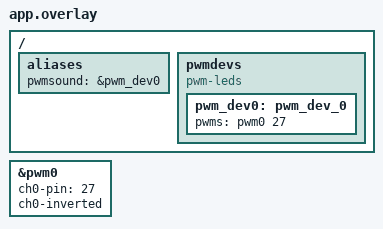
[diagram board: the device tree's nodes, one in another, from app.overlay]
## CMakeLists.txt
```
# SPDX-License-Identifier: Apache-2.0
#Setting to exclusively build for the Thingy
set(BOARD thingy52_nrf52832)
set(BOARD_FLASH_RUNNER jlink)
#set(DTC_OVERLAY_FILE boards/mpu9250.overlay)
set(CONF_FILE prj.conf)

cmake_minimum_required(VERSION 3.13.1)
#set(DTC_OVERLAY_FILE app.overlay)
find_package(Zephyr REQUIRED HINTS $ENV{ZEPHYR_BASE})
project(scu)

target_sources(app PRIVATE src/main.c 
        ../../oslib/scu_drivers/scu_ble/scu_ble.c
        #../../oslib/scu_drivers/scu_sensors/scu_sensors.c
        #../../oslib/scu_drivers/scu_io/scu_io.c
        )

#Add include_directories for libraries, path starts from this files location.
include_directories(app PUBLIC ../../oslib/scu_drivers/scu_ble
                    #app PUBLIC ../../oslib/scu_drivers/scu_sensors
                    #app PUBLIC ../../oslib/scu_drivers/scu_io
                    )


zephyr_library_include_directories(${ZEPHYR_BASE}/samples/bluetooth)
```

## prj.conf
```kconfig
#------------------------------------------------------------------------------
                                #Console RTT Console
#------------------------------------------------------------------------------
CONFIG_PRINTK=y
CONFIG_CBPRINTF_FP_SUPPORT=y
CONFIG_USE_SEGGER_RTT=y
CONFIG_SHELL_BACKEND_SERIAL=n
CONFIG_UART_CONSOLE=n
CONFIG_LOG=y
CONFIG_RTT_CONSOLE=y
CONFIG_NEWLIB_LIBC=y

#------------------------------------------------------------------------------
                                #BT Config
#------------------------------------------------------------------------------
CONFIG_BT=y
CONFIG_BT_SMP=y
CONFIG_BT_PERIPHERAL=y
CONFIG_BT_GATT_CLIENT=y
CONFIG_BT_CENTRAL=y

#-----------------------------------------------------------------------------
                                #Console MISC
#-----------------------------------------------------------------------------
CONFIG_GPIO=y
CONFIG_NEWLIB_LIBC_FLOAT_PRINTF=y
```

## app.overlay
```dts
&pwm0 {
  status = "okay";
  ch0-pin = <27>;
  ch0-inverted;
 };
/{
   
  aliases {
    pwmsound = &pwm_dev0;
};

pwmdevs {
  compatible = "pwm-leds";
   pwm_dev0: pwm_dev_0 {
  pwms = <&pwm0 27>;
  };
 };
 
};
```

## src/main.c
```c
/**
 ************************************************************************
 * @file main.c
 * @author Liana van Teijlingen
 * @date 04.04.2021
 * @brief Initialises scu threads
 **********************************************************************
 * */

#include <zephyr.h>
#include <device.h>
#include <devicetree.h>
#include <drivers/gpio.h>
#include <data/json.h>

#include <bluetooth/bluetooth.h>
#include <bluetooth/hci.h>
#include <bluetooth/conn.h>
#include <bluetooth/uuid.h>
#include <bluetooth/gatt.h>

#include <init.h>
#include <drivers/gpio.h>
#include <sys/printk.h>
#include "scu_ble.h"
//#include "scu_io.h"

K_THREAD_DEFINE(ble_connect, 1024, thread_ble_connect, NULL, NULL, NULL, THREAD_PRIORITY_BLE_CONNECT_THREAD, 0, 0);
K_THREAD_DEFINE(ble_discover, 1024, thread_ble_discover, NULL, NULL, NULL, THREAD_PRIORITY_BLE_CONNECT_THREAD, 0, 0);
K_THREAD_DEFINE(send_message, 1024, thread_send_message, NULL, NULL, NULL, 20, 0, 0);
// K_THREAD_DEFINE(get_message, 4096, thread_get_message, NULL, NULL, NULL, 20, 0, 0);
// K_THREAD_DEFINE(read_button, 512, thread_read_button, NULL, NULL, NULL, 20, 0, 0);

void main(void)
{

    // led_gpio_enable();
    // init_buzzer();
    // init_hts();
    // init_lps();
    // init_ccs();
    // init_lis();
}
```
